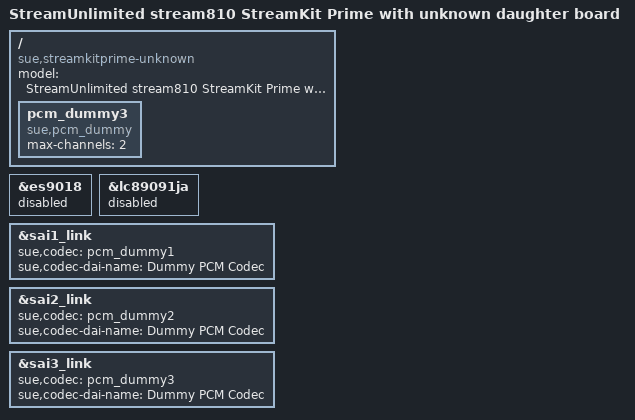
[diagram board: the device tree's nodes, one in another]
/*
 * This program is free software; you can redistribute it and/or modify
 * it under the terms of the GNU General Public License version 2 as
 * published by the Free Software Foundation.
 */

/dts-v1/;

#include "imx7d-sue-s810-extended-0.dtsi"
#include "imx7d-sue-streamkitprime-common-0.dtsi"
#include "imx7d-sue-streamkitprime-highend-0.dtsi"

/ {
	model = "StreamUnlimited stream810 StreamKit Prime with unknown daughter board";
	compatible = "sue,streamkitprime-unknown", "sue,streamkitprime", "sue,stream810", "fsl,imx7d";

	pcm_dummy3: pcm_dummy3 {
		compatible = "sue,pcm_dummy";
		max-channels = <2>;
	};
};

/* Disable codecs */
&es9018 {
	status = "disabled";
};

&lc89091ja {
	status = "disabled";
};

/* Use dummy codecs for all SAIs */
&sai1_link {
	sue,codec = <&pcm_dummy1>;
	sue,codec-dai-name = "Dummy PCM Codec";
};

&sai2_link {
	sue,codec = <&pcm_dummy2>;
	sue,codec-dai-name = "Dummy PCM Codec";
};

&sai3_link {
	sue,codec = <&pcm_dummy3>;
	sue,codec-dai-name = "Dummy PCM Codec";
};
